# STM32F412CEU6 register map
File version: 1.0
Registers are 32-bit, access not given, reset 0x0 unless marked. A register's access mark holds for its fields unless they carry their own. Offsets are from the block's base; [hi:lo] are bit positions; {n}, {i} and the like mark numbered series; 'fields as' and 'values as' point back to an identical list.

## TIM13
Base 0x40001C00
Same registers: TIM14 0x40002000, TIM10 0x40014400, TIM11 0x40014800
0x00 CR1
  [9:8] CKD, [7] ARPE, [31:3] s, [2] URS, [1] UDIS, [0] CEN
0x08 SMCR
  [31:0] s
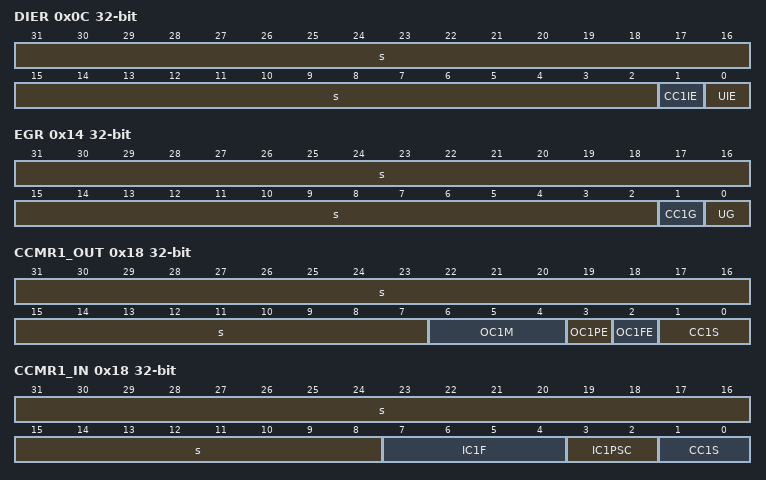
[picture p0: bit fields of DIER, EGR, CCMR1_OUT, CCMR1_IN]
0x0C DIER
  [31:2] s, [1] CC1IE, [0] UIE
0x10 SR
  [9] CC1OF, [31:2] s, [1] CC1IF, [0] UIF
0x14 EGR
  [31:2] s, [1] CC1G, [0] UG
0x18 CCMR1_OUT
  [31:7] s, [6:4] OC1M, [3] OC1PE, [2] OC1FE, [1:0] CC1S
0x18 CCMR1_IN
  [31:8] s, [7:4] IC1F, [3:2] IC1PSC, [1:0] CC1S
0x20 CCER
  [3] CC1NP, [31:2] s, [1] CC1P, [0] CC1E
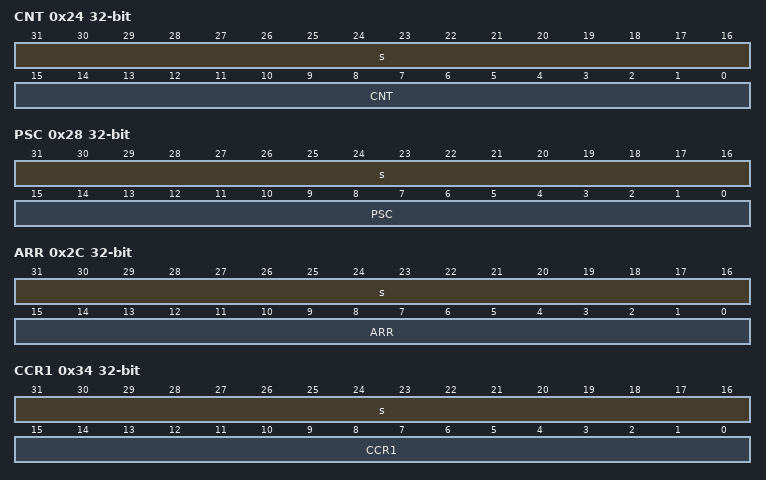
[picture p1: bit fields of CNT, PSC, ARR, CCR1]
0x24 CNT
  [31:16] s, [15:0] CNT
0x28 PSC
  [31:16] s, [15:0] PSC
0x2C ARR
  [31:16] s, [15:0] ARR
0x34 CCR1
  [31:16] s, [15:0] CCR1
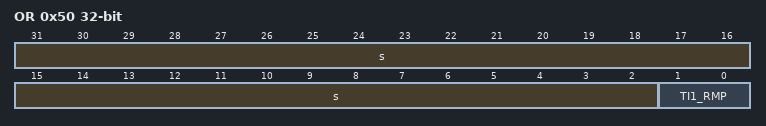
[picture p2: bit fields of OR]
0x50 OR
  [31:2] s, [1:0] TI1_RMP

## BKP
Base 0x40002800
0x00 TR
  [22] PM, [21:20] HT, [19:16] HU, [14:12] MNT, [11:8] MNU, [31:7] s, [6:4] ST, [3:0] SU
0x04 DR
  [23:20] YT, [19:16] YU, [15:13] WDU, [12] MT, [11:8] MU, [31:6] s, [5:4] DT, [3:0] DU
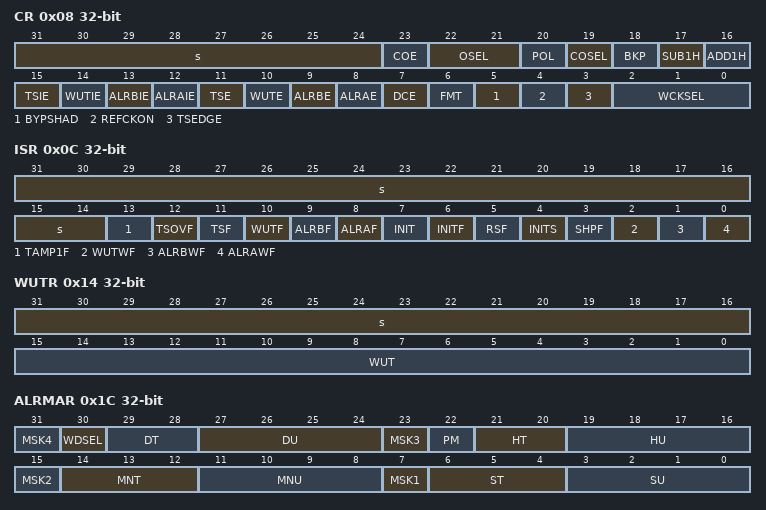
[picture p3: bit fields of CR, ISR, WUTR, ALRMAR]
0x08 CR
  [31:24] s, [23] COE, [22:21] OSEL, [20] POL, [19] COSEL, [18] BKP, [17] SUB1H, [16] ADD1H, [15] TSIE, [14] WUTIE, [13] ALRBIE, [12] ALRAIE, [11] TSE, [10] WUTE, [9] ALRBE, [8] ALRAE, [7] DCE, [6] FMT, [5] BYPSHAD, [4] REFCKON, [3] TSEDGE, [2:0] WCKSEL
0x0C ISR
  [31:14] s, [13] TAMP1F, [12] TSOVF, [11] TSF, [10] WUTF, [9] ALRBF, [8] ALRAF, [7] INIT, [6] INITF, [5] RSF, [4] INITS, [3] SHPF, [2] WUTWF, [1] ALRBWF, [0] ALRAWF
0x10 PRER
  [22:16] PREDIV_A, [31:15] s, [14:0] PREDIV_S
0x14 WUTR
  [31:16] s, [15:0] WUT
0x18 CALIBR
  [7] DCS, [31:5] s, [4:0] DC
0x1C ALRMAR
  [8n-1] MSK{n} (n=1..4), [30] WDSEL, [29:28] DT, [27:24] DU, [22] PM, [21:20] HT, [19:16] HU, [14:12] MNT, [11:8] MNU, [6:4] ST, [3:0] SU
0x20 ALRMBR
  [31] MSK4, [30] WDSEL, [29:28] DT, [27:24] DU, [23] MSK3, [22] PM, [21:20] HT, [19:16] HU, [14:12] MNT, [11:8] MNU, [15:7] MSK2, [6:4] ST, [3:0] SU
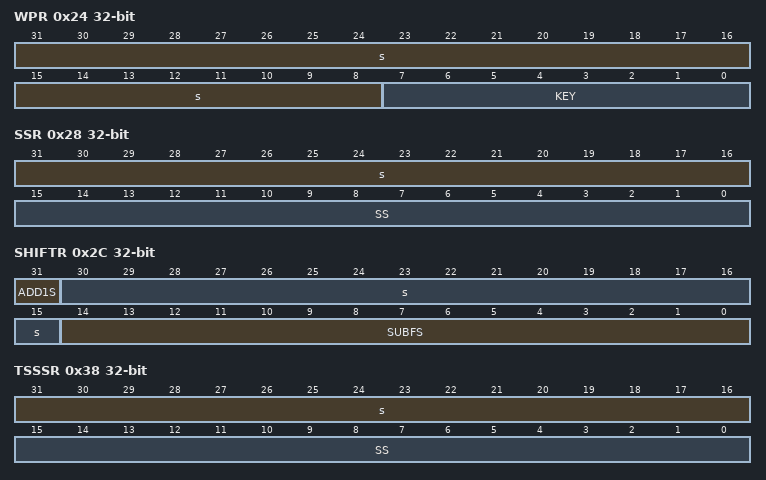
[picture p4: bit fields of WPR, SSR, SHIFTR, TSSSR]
0x24 WPR
  [31:8] s, [7:0] KEY
0x28 SSR
  [31:16] s, [15:0] SS
0x2C SHIFTR
  [31] ADD1S, [30:15] s, [14:0] SUBFS
0x30 TSTR
  fields as TR
0x38 TSSSR
  [31:16] s, [15:0] SS
0x3C CALR
  [15] CALP, [14] CALW8, [13] CALW16, [31:9] s, [8:0] CALM
0x40 TAFCR
  [18] ALARMOUTTYPE, [17] TSINSEL, [16] TAMP1INSEL, [15] TAMPPUDIS, [14:13] TAMPPRCH, [12:11] TAMPFLT, [10:8] TAMPFREQ, [7] TAMPTS, [31:3] s, [2] TAMPIE, [1] TAMP1ETRG, [0] TAMP1E
0x44 ALRMASSR
  [27:24] MASKSS, [31:15] s, [14:0] SS
0x48 ALRMBSSR
  [27:24] MASKSS, [31:15] s, [14:0] SS
{0x50+4i} BKP{i}R (i=0..19)
  [31:0] BKP

## RTC
Base 0x40002800
Registers as BKP; these are added or differ:
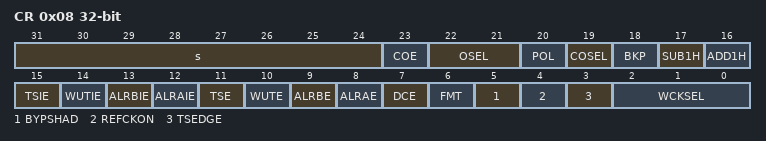
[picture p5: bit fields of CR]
0x08 CR
  fields as BKP.CR
{0x50+4i} BKP{i}R (i=0..19)
  [31:0] BKP

## WWDG
Base 0x40002C00
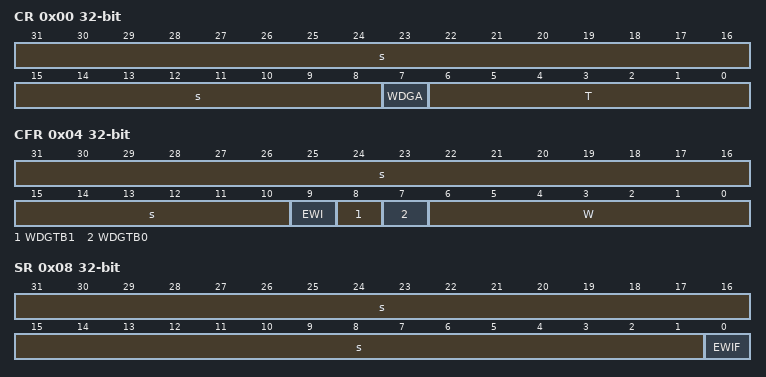
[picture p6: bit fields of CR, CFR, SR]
0x00 CR
  [31:8] s, [7] WDGA, [6:0] T
0x04 CFR
  [31:10] s, [9] EWI, [8] WDGTB1, [7] WDGTB0, [6:0] W
0x08 SR
  [31:1] s, [0] EWIF

## IWDG
Base 0x40003000
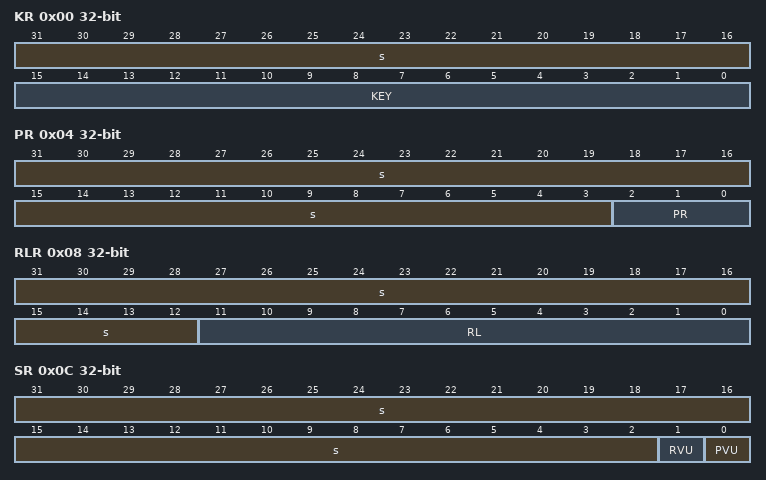
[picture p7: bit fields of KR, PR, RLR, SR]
0x00 KR
  [31:16] s, [15:0] KEY
0x04 PR
  [31:3] s, [2:0] PR
0x08 RLR
  [31:12] s, [11:0] RL
0x0C SR
  [31:2] s, [1] RVU, [0] PVU

## SPI2
Base 0x40003800
Same registers: SPI3 0x40003C00, SPI1 0x40013000, SPI4 0x40013400, SPI5 0x40015000, QSPI 0xA0001000
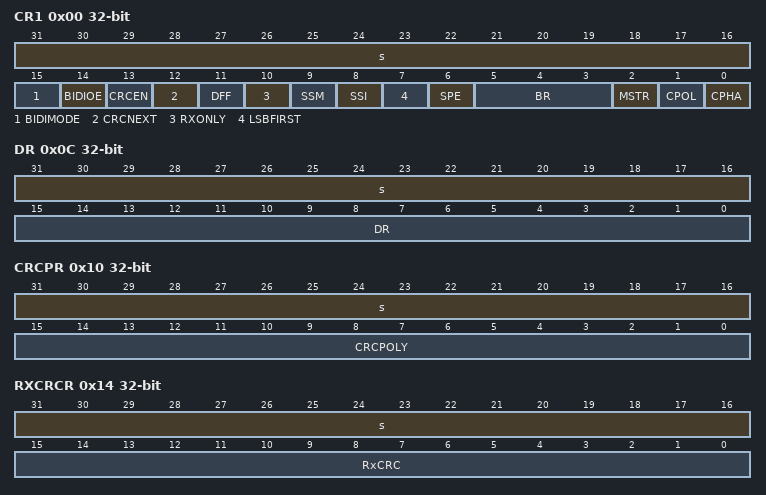
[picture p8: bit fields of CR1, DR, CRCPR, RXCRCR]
0x00 CR1
  [31:16] s, [15] BIDIMODE, [14] BIDIOE, [13] CRCEN, [12] CRCNEXT, [11] DFF, [10] RXONLY, [9] SSM, [8] SSI, [7] LSBFIRST, [6] SPE, [5:3] BR, [2] MSTR, [1] CPOL, [0] CPHA
0x04 CR2
  [7] TXEIE, [6] RXNEIE, [5] ERRIE, [4] FRF, [31:3] s, [2] SSOE, [1] TXDMAEN, [0] RXDMAEN
0x08 SR
0x0C DR
  [31:16] s, [15:0] DR
0x10 CRCPR
  [31:16] s, [15:0] CRCPOLY
0x14 RXCRCR
  [31:16] s, [15:0] RxCRC
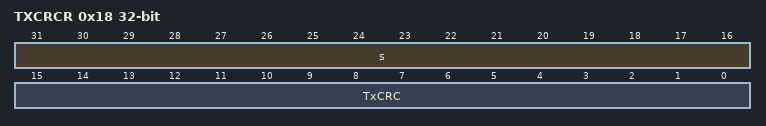
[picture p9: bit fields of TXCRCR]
0x18 TXCRCR
  [31:16] s, [15:0] TxCRC
0x1C I2SCFGR
  [12] ASTREN, [11] I2SMOD, [10] I2SE, [9:8] I2SCFG, [7] PCMSYNC, [31:6] s, [5:4] I2SSTD, [3] CKPOL, [2:1] DATLEN, [0] CHLEN
0x20 I2SPR

## USART2
Base 0x40004400
Same registers: USART3 0x40004800, USART1 0x40011000, USART6 0x40011400
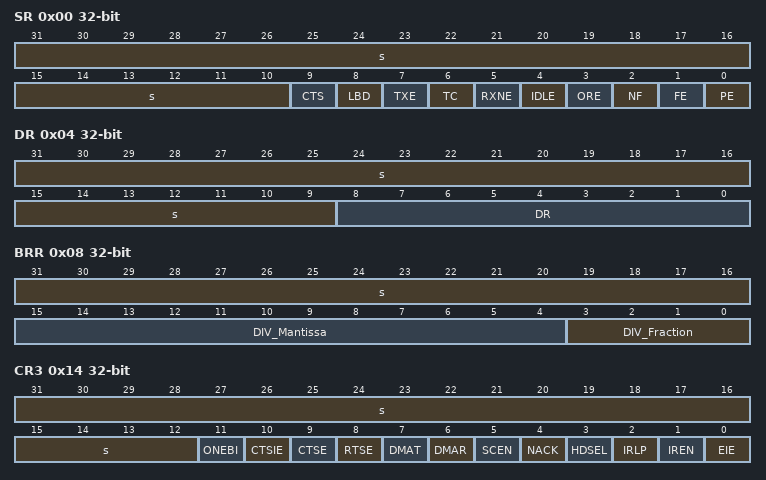
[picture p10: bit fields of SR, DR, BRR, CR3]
0x00 SR
  [31:10] s, [9] CTS, [8] LBD, [7] TXE, [6] TC, [5] RXNE, [4] IDLE, [3] ORE, [2] NF, [1] FE, [0] PE
0x04 DR
  [31:9] s, [8:0] DR
0x08 BRR
  [31:16] s, [15:4] DIV_Mantissa, [3:0] DIV_Fraction
0x0C CR1
  [15] OVER8, [31:14] s, [13] UE, [12] M, [11] WAKE, [10] PCE, [9] PS, [8] PEIE, [7] TXEIE, [6] TCIE, [5] RXNEIE, [4] IDLEIE, [3] TE, [2] RE, [1] RWU, [0] SBK
0x10 CR2
  [14] LINEN, [13:12] STOP, [11] CLKEN, [10] CPOL, [9] CPHA, [8] LBCL, [6] LBDIE, [5] LBDL, [31:4] s, [3:0] ADD
0x14 CR3
  [31:12] s, [11] ONEBI, [10] CTSIE, [9] CTSE, [8] RTSE, [7] DMAT, [6] DMAR, [5] SCEN, [4] NACK, [3] HDSEL, [2] IRLP, [1] IREN, [0] EIE
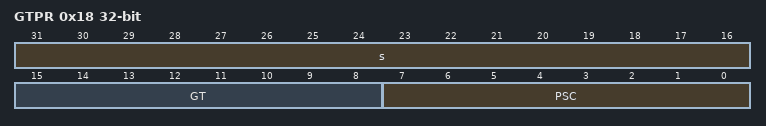
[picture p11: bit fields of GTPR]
0x18 GTPR
  [31:16] s, [15:8] GT, [7:0] PSC
